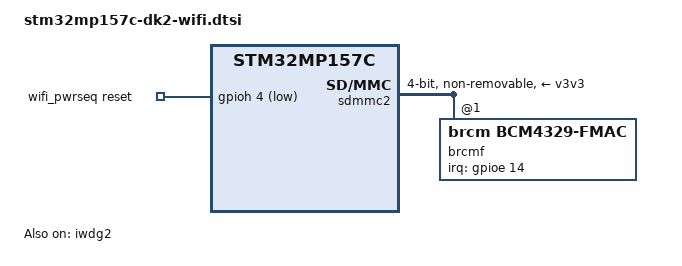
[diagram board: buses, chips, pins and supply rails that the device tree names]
// SPDX-License-Identifier: (GPL-2.0-only OR BSD-3-Clause)
/*
 * STM32MP157F-DK2: WiFi/BT (Murata 1DX / CYW43438) via SDMMC2 (0x58007000)
 * WL_REG_ON : GPIOH4 active-low
 * WL_HOST_WAKE: GPIOE14 level-low
 */
#include <dt-bindings/gpio/gpio.h>
#include <dt-bindings/interrupt-controller/irq.h>

/* Enable IWDG2 so the kernel watchdog driver manages the watchdog
 * started by U-Boot (watchdog@5a002000, 32s timeout). */
&iwdg2 {
	timeout-sec = <32>;
	status = "okay";
};


/ {
	wifi_pwrseq: wifi-pwrseq {
		compatible = "mmc-pwrseq-simple";
		reset-gpios = <&gpioh 4 GPIO_ACTIVE_LOW>;
		post-power-on-delay-ms = <200>;
	};
};

&sdmmc2 {
	pinctrl-names = "default", "opendrain", "sleep";
	pinctrl-0 = <&sdmmc2_b4_pins_a>;
	pinctrl-1 = <&sdmmc2_b4_od_pins_a>;
	pinctrl-2 = <&sdmmc2_b4_sleep_pins_a>;
	non-removable;
	st,neg-edge;
	bus-width = <4>;
	vmmc-supply = <&v3v3>;
	mmc-pwrseq = <&wifi_pwrseq>;
	cap-sdio-irq;
	max-frequency = <25000000>;
	no-1-8-v;
	#address-cells = <1>;
	#size-cells = <0>;
	status = "okay";

	brcmf: wifi@1 {
		reg = <1>;
		compatible = "brcm,bcm4329-fmac";
		interrupt-parent = <&gpioe>;
		interrupts = <14 IRQ_TYPE_LEVEL_LOW>;
		interrupt-names = "host-wake";
	};
};
